# STM32F103 register map
File version: 1.0
CPU: CM3 r1p1, little endian, 4 interrupt priority bits
Registers are 32-bit, read-write, reset 0x0 unless marked. A register's access mark holds for its fields unless they carry their own. Offsets are from the block's base; [hi:lo] are bit positions; {n}, {i} and the like mark numbered series.

## SDIO — Secure digital input/output interface
Base 0x40018000
0x00 POWER — Bits 1:0 = PWRCTRL: Power supply control bits
  [1:0] PWRCTRL
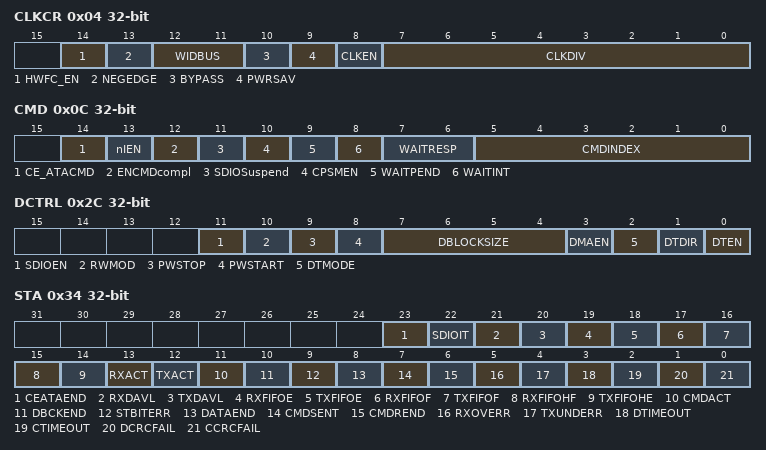
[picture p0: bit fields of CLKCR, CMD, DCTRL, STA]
0x04 CLKCR — SDI clock control register (SDIO_CLKCR)
  [14] HWFC_EN — HW Flow Control enable
  [13] NEGEDGE — SDIO_CK dephasing selection bit
  [12:11] WIDBUS — Wide bus mode enable bit
  [10] BYPASS — Clock divider bypass enable bit
  [9] PWRSAV — Power saving configuration bit
  [8] CLKEN — Clock enable bit
  [7:0] CLKDIV — Clock divide factor
0x08 ARG — Bits 31:0 = : Command argument
  [31:0] CMDARG — Command argument
0x0C CMD — SDIO command register (SDIO_CMD)
  [14] CE_ATACMD, [13] nIEN, [12] ENCMDcompl, [11] SDIOSuspend, [10] CPSMEN, [9] WAITPEND, [8] WAITINT, [7:6] WAITRESP, [5:0] CMDINDEX
0x10 RESPCMD ro — SDIO command register
  [5:0] RESPCMD
0x14 RESPI1 ro — Bits 31:0 = CARDSTATUS1
  [31:0] CARDSTATUS1
{0x10+4i} RESP{i} ro (i=2..4) — Bits 31:0 = CARDSTATUS{i}
  [31:0] CARDSTATUS{i}
0x24 DTIMER — Bits 31:0 = DATATIME: Data timeout period
  [31:0] DATATIME — Data timeout period
0x28 DLEN — Bits 24:0 = DATALENGTH: Data length value
  [24:0] DATALENGTH — Data length value
0x2C DCTRL — SDIO data control register (SDIO_DCTRL)
  [11] SDIOEN, [10] RWMOD, [9] PWSTOP, [8] PWSTART, [7:4] DBLOCKSIZE, [3] DMAEN, [2] DTMODE, [1] DTDIR, [0] DTEN
0x30 DCOUNT ro — Bits 24:0 = DATACOUNT: Data count value
  [24:0] DATACOUNT — Data count value
0x34 STA ro — SDIO status register (SDIO_STA)
  [23] CEATAEND, [22] SDIOIT, [21] RXDAVL, [20] TXDAVL, [19] RXFIFOE, [18] TXFIFOE, [17] RXFIFOF, [16] TXFIFOF, [15] RXFIFOHF, [14] TXFIFOHE, [13] RXACT, [12] TXACT, [11] CMDACT, [10] DBCKEND, [9] STBITERR, [8] DATAEND, [7] CMDSENT, [6] CMDREND, [5] RXOVERR, [4] TXUNDERR, [3] DTIMEOUT, [2] CTIMEOUT, [1] DCRCFAIL, [0] CCRCFAIL
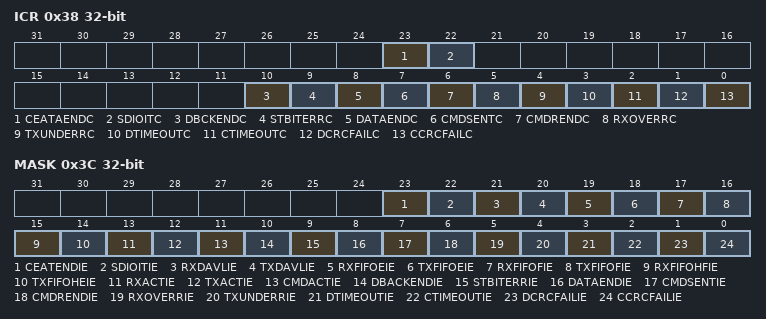
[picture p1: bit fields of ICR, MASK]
0x38 ICR — SDIO interrupt clear register (SDIO_ICR)
  [23] CEATAENDC, [22] SDIOITC, [10] DBCKENDC, [9] STBITERRC, [8] DATAENDC, [7] CMDSENTC, [6] CMDRENDC, [5] RXOVERRC, [4] TXUNDERRC, [3] DTIMEOUTC, [2] CTIMEOUTC, [1] DCRCFAILC, [0] CCRCFAILC
0x3C MASK — SDIO mask register (SDIO_MASK)
  [23] CEATENDIE, [22] SDIOITIE, [21] RXDAVLIE, [20] TXDAVLIE, [19] RXFIFOEIE, [18] TXFIFOEIE, [17] RXFIFOFIE, [16] TXFIFOFIE, [15] RXFIFOHFIE, [14] TXFIFOHEIE, [13] RXACTIE, [12] TXACTIE, [11] CMDACTIE, [10] DBACKENDIE, [9] STBITERRIE, [8] DATAENDIE, [7] CMDSENTIE, [6] CMDRENDIE, [5] RXOVERRIE, [4] TXUNDERRIE, [3] DTIMEOUTIE, [2] CTIMEOUTIE, [1] DCRCFAILIE, [0] CCRCFAILIE
0x48 FIFOCNT ro — Bits 23:0 = FIFOCOUNT: Remaining number of words to be written to or read from the FIFO
  [23:0] FIF0COUNT
0x80 FIFO — bits 31:0 = FIFOData: Receive and transmit FIFO data
  [31:0] FIFOData

## RTC — Real time clock
Base 0x40002800
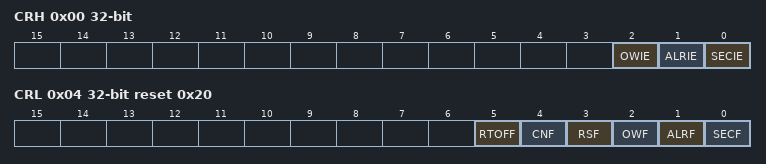
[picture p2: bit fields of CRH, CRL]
0x00 CRH — RTC Control Register High
  [2] OWIE — Overflow interrupt Enable
  [1] ALRIE — Alarm interrupt Enable
  [0] SECIE — Second interrupt Enable
0x04 CRL access per field reset 0x20 — RTC Control Register Low
  [5] RTOFF ro — RTC operation OFF
  [4] CNF rw — Configuration Flag
  [3] RSF rw — Registers Synchronized Flag
  [2] OWF rw — Overflow Flag
  [1] ALRF rw — Alarm Flag
  [0] SECF rw — Second Flag
0x08 PRLH wo — RTC Prescaler Load Register High
  [3:0] PRLH
0x0C PRLL wo reset 0x8000 — RTC Prescaler Load Register Low
  [15:0] PRLL — RTC Prescaler Divider Register Low
0x10 DIVH ro — RTC Prescaler Divider Register High
  [3:0] DIVH — RTC prescaler divider register high
0x14 DIVL ro reset 0x8000 — RTC Prescaler Divider Register Low
  [15:0] DIVL — RTC prescaler divider register Low
0x18 CNTH — RTC Counter Register High
  [15:0] CNTH — RTC counter register high
0x1C CNTL — RTC Counter Register Low
  [15:0] CNTL — RTC counter register Low
0x20 ALRH wo reset 0xFFFF — RTC Alarm Register High
  [15:0] ALRH — RTC alarm register high
0x24 ALRL wo reset 0xFFFF — RTC Alarm Register Low
  [15:0] ALRL — RTC alarm register low
